# PRCM register map
Vendor: Texas Instruments
Peripheral module from a debugger description file (folder CC26x4).
Registers are 32-bit, access per field, reset 0x0 unless marked. A register's access mark holds for its fields unless they carry their own. Offsets are as the file gives them; lines under a group give offsets from that group; [hi:lo] are bit positions; {n}, {i} and the like mark numbered series; 'fields as' and 'values as' point back to an identical list; <NAME> marks a mode.

## PRCM — Power, Reset and Clock Management
0x00 INFRCLKDIVR — Infrastructure Clock Division Factor For Run Mode
  [1:0] RATIO rw — Division rate for clocks driving modules in the MCU_AON domain when system CPU is in run mode. Division ratio affects both infrastructure clock and perbusull clock.
    3=DIV32 (Divide by 32); 2=DIV8 (Divide by 8); 1=DIV2 (Divide by 2); 0=DIV1 (Divide by 1)
0x04 INFRCLKDIVS — Infrastructure Clock Division Factor For Sleep Mode
  [1:0] RATIO rw — Division rate for clocks driving modules in the MCU_AON domain when system CPU is in sleep mode. Division ratio affects both infrastructure clock and perbusull clock.
    values as INFRCLKDIVR.RATIO
0x08 INFRCLKDIVDS — Infrastructure Clock Division Factor For DeepSleep Mode
  [1:0] RATIO rw — Division rate for clocks driving modules in the MCU_AON domain when system CPU is in deepsleep mode. Division ratio affects both infrastructure clock and perbusull clock.
    values as INFRCLKDIVR.RATIO
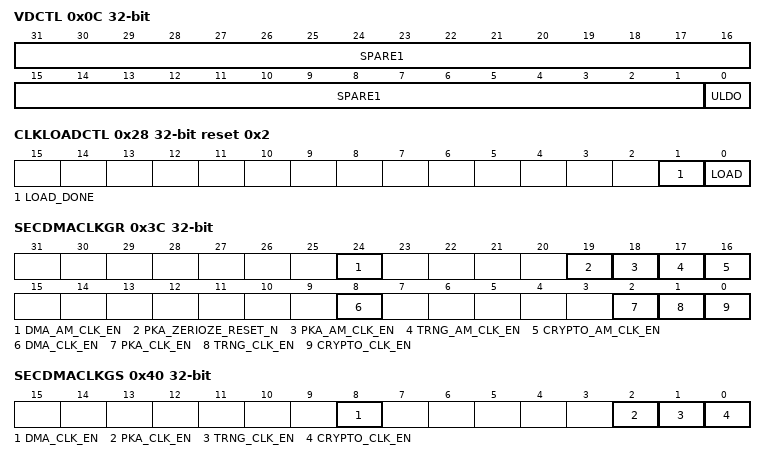
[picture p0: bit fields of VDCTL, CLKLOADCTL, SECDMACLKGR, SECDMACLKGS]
0x0C VDCTL rw — MCU Voltage Domain Control
  [31:1] SPARE1 — Software should not rely on the value of a reserved. Writing any other value than the reset value may result in undefined behavior.
  [0] ULDO — Request PMCTL to switch to uLDO. 0: No request 1: Assert request when possible The bit will have no effect before the following requirements are met: 1. PDCTL1.CPU_ON = 0 2. PDCTL1.VIMS_MODE = x0 3. SECDMACLKGDS.DMA_CLK_EN = 0 and S.CRYPTO_CLK_EN] = 0 and SECDMACLKGR.DMA_AM_CLK_EN = 0 (Note: Settings must be loaded with CLKLOADCTL.LOAD) 4. SECDMACLKGDS.CRYPTO_CLK_EN = 0 and SECDMACLKGR.CRYPTO_AM_CLK_EN = 0 (Note: Settings must be loaded with CLKLOADCTL.LOAD) 5. I2SCLKGDS.CLK_EN = 0 and I2SCLKGR.AM_CLK_EN = 0 (Note: Settings must be loaded with CLKLOADCTL.LOAD) 6. RFC do no request access to BUS 7. System CPU in deepsleep
0x28 CLKLOADCTL reset 0x2 — Load PRCM Settings To CLKCTRL Power Domain
  [1] LOAD_DONE ro — Status of LOAD. Will be cleared to 0 when any of the registers requiring a LOAD is written to, and be set to 1 when a LOAD is done. Note that writing no change to a register will result in the LOAD_DONE being cleared. 0 : One or more registers have been write accessed after last LOAD 1 : No registers are write accessed after last LOAD
  [0] LOAD wo — 0: No action 1: Load settings to CLKCTRL. Bit is HW cleared. Multiple changes to settings may be done before LOAD is written once so all changes takes place at the same time. LOAD can also be done after single setting updates. Registers that needs to be followed by LOAD before settings being applied are: - SYSBUSCLKDIV - CPUCLKDIV - PERBUSCPUCLKDIV - PERDMACLKDIV - PERBUSCPUCLKG - RFCCLKG - VIMSCLKG - SECDMACLKGR - SECDMACLKGS - SECDMACLKGDS - GPIOCLKGR - GPIOCLKGS - GPIOCLKGDS - GPTCLKGR - GPTCLKGS - GPTCLKGDS - GPTCLKDIV - I2CCLKGR - I2CCLKGS - I2CCLKGDS - SPICLKGR - SPICLKGS - SPICLKGDS - UARTCLKGR - UARTCLKGS - UARTCLKGDS - I2SCLKGR - I2SCLKGS - I2SCLKGDS - I2SBCLKSEL - I2SCLKCTL - I2SMCLKDIV - I2SBCLKDIV - I2SWCLKDIV - MCUSRAMCFG
0x2C RFCCLKG reset 0x1 — RFC Clock Gate
  [0] CLK_EN rw — 0: Disable Clock 1: Enable clock if RFC power domain is on For changes to take effect, CLKLOADCTL.LOAD needs to be written
0x30 VIMSCLKG reset 0x3 — VIMS Clock Gate
  [1:0] CLK_EN rw — 00: Disable clock 01: Disable clock when SYSBUS clock is disabled 11: Enable clock For changes to take effect, CLKLOADCTL.LOAD needs to be written
0x3C SECDMACLKGR — SEC (PKA And TRNG And CRYPTO) And UDMA Clock Gate For Run And All Modes
  [24] DMA_AM_CLK_EN rw — 0: No force 1: Force clock on for all modes (Run, Sleep and Deep Sleep) Overrides DMA_CLK_EN, SECDMACLKGS.DMA_CLK_EN and SECDMACLKGDS.DMA_CLK_EN when enabled. SYSBUS clock will always run when enabled For changes to take effect, CLKLOADCTL.LOAD needs to be written
  [19] PKA_ZERIOZE_RESET_N rw — Zeroization logic hardware reset. 0: pka_zeroize logic inactive. 1: pka_zeroize of memory is enabled. This register must remain active until the memory are completely zeroized which requires 256 periods on systembus clock.
  [18] PKA_AM_CLK_EN rw — 0: No force 1: Force clock on for all modes (Run, Sleep and Deep Sleep) Overrides PKA_CLK_EN, SECDMACLKGS.PKA_CLK_EN and SECDMACLKGDS.PKA_CLK_EN when enabled. For changes to take effect, CLKLOADCTL.LOAD needs to be written
  [17] TRNG_AM_CLK_EN rw — 0: No force 1: Force clock on for all modes (Run, Sleep and Deep Sleep) Overrides TRNG_CLK_EN, SECDMACLKGS.TRNG_CLK_EN and SECDMACLKGDS.TRNG_CLK_EN when enabled. For changes to take effect, CLKLOADCTL.LOAD needs to be written
  [16] CRYPTO_AM_CLK_EN rw — 0: No force 1: Force clock on for all modes (Run, Sleep and Deep Sleep) Overrides CRYPTO_CLK_EN, SECDMACLKGS.CRYPTO_CLK_EN and SECDMACLKGDS.CRYPTO_CLK_EN when enabled. SYSBUS clock will always run when enabled For changes to take effect, CLKLOADCTL.LOAD needs to be written
  [8] DMA_CLK_EN rw — 0: Disable clock 1: Enable clock Can be forced on by DMA_AM_CLK_EN For changes to take effect, CLKLOADCTL.LOAD needs to be written
  [2] PKA_CLK_EN rw — 0: Disable clock 1: Enable clock Can be forced on by PKA_AM_CLK_EN For changes to take effect, CLKLOADCTL.LOAD needs to be written
  [1] TRNG_CLK_EN rw — 0: Disable clock 1: Enable clock Can be forced on by TRNG_AM_CLK_EN For changes to take effect, CLKLOADCTL.LOAD needs to be written
  [0] CRYPTO_CLK_EN rw — 0: Disable clock 1: Enable clock Can be forced on by CRYPTO_AM_CLK_EN For changes to take effect, CLKLOADCTL.LOAD needs to be written
0x40 SECDMACLKGS — SEC (PKA And TRNG And CRYPTO) And UDMA Clock Gate For Sleep Mode
  [8] DMA_CLK_EN rw — 0: Disable clock 1: Enable clock Can be forced on by SECDMACLKGR.DMA_AM_CLK_EN For changes to take effect, CLKLOADCTL.LOAD needs to be written
  [2] PKA_CLK_EN rw — 0: Disable clock 1: Enable clock Can be forced on by SECDMACLKGR.PKA_AM_CLK_EN For changes to take effect, CLKLOADCTL.LOAD needs to be written
  [1] TRNG_CLK_EN rw — 0: Disable clock 1: Enable clock Can be forced on by SECDMACLKGR.TRNG_AM_CLK_EN For changes to take effect, CLKLOADCTL.LOAD needs to be written
  [0] CRYPTO_CLK_EN rw — 0: Disable clock 1: Enable clock Can be forced on by SECDMACLKGR.CRYPTO_AM_CLK_EN For changes to take effect, CLKLOADCTL.LOAD needs to be written
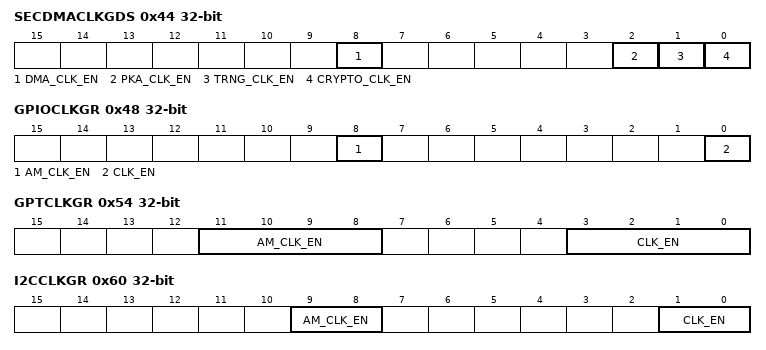
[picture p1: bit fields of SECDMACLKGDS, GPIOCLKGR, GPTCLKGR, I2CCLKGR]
0x44 SECDMACLKGDS — SEC (PKA And TRNG and CRYPTO) And UDMA Clock Gate For Deep Sleep Mode
  [8] DMA_CLK_EN rw — 0: Disable clock 1: Enable clock Can be forced on by SECDMACLKGR.DMA_AM_CLK_EN For changes to take effect, CLKLOADCTL.LOAD needs to be written
  [2] PKA_CLK_EN rw — 0: Disable clock 1: Enable clock Can be forced on by SECDMACLKGR.PKA_AM_CLK_EN For changes to take effect, CLKLOADCTL.LOAD needs to be written
  [1] TRNG_CLK_EN rw — 0: Disable clock 1: Enable clock SYSBUS clock will always run when enabled Can be forced on by SECDMACLKGR.TRNG_AM_CLK_EN For changes to take effect, CLKLOADCTL.LOAD needs to be written
  [0] CRYPTO_CLK_EN rw — 0: Disable clock 1: Enable clock SYSBUS clock will always run when enabled Can be forced on by SECDMACLKGR.CRYPTO_AM_CLK_EN For changes to take effect, CLKLOADCTL.LOAD needs to be written
0x48 GPIOCLKGR — GPIO Clock Gate For Run And All Modes
  [8] AM_CLK_EN rw — 0: No force 1: Force clock on for all modes (Run, Sleep and Deep Sleep) Overrides CLK_EN, GPIOCLKGS.CLK_EN and GPIOCLKGDS.CLK_EN when enabled. For changes to take effect, CLKLOADCTL.LOAD needs to be written
  [0] CLK_EN rw — 0: Disable clock 1: Enable clock Can be forced on by AM_CLK_EN For changes to take effect, CLKLOADCTL.LOAD needs to be written
0x4C GPIOCLKGS — GPIO Clock Gate For Sleep Mode
  [0] CLK_EN rw — 0: Disable clock 1: Enable clock Can be forced on by GPIOCLKGR.AM_CLK_EN For changes to take effect, CLKLOADCTL.LOAD needs to be written
0x50 GPIOCLKGDS — GPIO Clock Gate For Deep Sleep Mode
  fields as GPIOCLKGS
0x54 GPTCLKGR — GPT Clock Gate For Run And All Modes
  [11:8] AM_CLK_EN rw — Each bit below has the following meaning: 0: No force 1: Force clock on for all modes (Run, Sleep and Deep Sleep) Overrides CLK_EN, GPTCLKGS.CLK_EN and GPTCLKGDS.CLK_EN when enabled. ENUMs can be combined For changes to take effect, CLKLOADCTL.LOAD needs to be written
    8=AM_GPT3 (Enable clock for GPT3 in all modes); 4=AM_GPT2 (Enable clock for GPT2 in all modes); 2=AM_GPT1 (Enable clock for GPT1 in all modes); 1=AM_GPT0 (Enable clock for GPT0 in all modes)
  [3:0] CLK_EN rw — Each bit below has the following meaning: 0: Disable clock 1: Enable clock Can be forced on by AM_CLK_EN ENUMs can be combined For changes to take effect, CLKLOADCTL.LOAD needs to be written
    8=GPT3 (Enable clock for GPT3); 4=GPT2 (Enable clock for GPT2); 2=GPT1 (Enable clock for GPT1); 1=GPT0 (Enable clock for GPT0)
0x58 GPTCLKGS — GPT Clock Gate For Sleep Mode
  [3:0] CLK_EN rw — Each bit below has the following meaning: 0: Disable clock 1: Enable clock Can be forced on by GPTCLKGR.AM_CLK_EN ENUMs can be combined For changes to take effect, CLKLOADCTL.LOAD needs to be written
    values as GPTCLKGR.CLK_EN
0x5C GPTCLKGDS — GPT Clock Gate For Deep Sleep Mode
  fields as GPTCLKGS
0x60 I2CCLKGR — I2C Clock Gate For Run And All Modes
  [9:8] AM_CLK_EN rw — 0: No force 1: Force clock on for all modes (Run, Sleep and Deep Sleep) Overrides CLK_EN, I2CCLKGS.CLK_EN and I2CCLKGDS.CLK_EN when enabled. For changes to take effect, CLKLOADCTL.LOAD needs to be written
    2=I2C1 (Enable clock for I2C1); 1=I2C0 (Enable clock for I2C0)
  [1:0] CLK_EN rw — 0: Disable clock 1: Enable clock Can be forced on by AM_CLK_EN For changes to take effect, CLKLOADCTL.LOAD needs to be written
    values as AM_CLK_EN
0x64 I2CCLKGS — I2C Clock Gate For Sleep Mode
  [1:0] CLK_EN rw — 0: Disable clock 1: Enable clock Can be forced on by I2CCLKGR.AM_CLK_EN For changes to take effect, CLKLOADCTL.LOAD needs to be written
    values as I2CCLKGR.AM_CLK_EN
0x68 I2CCLKGDS — I2C Clock Gate For Deep Sleep Mode
  [0] CLK_EN rw — 0: Disable clock 1: Enable clock Can be forced on by I2CCLKGR.AM_CLK_EN For changes to take effect, CLKLOADCTL.LOAD needs to be written
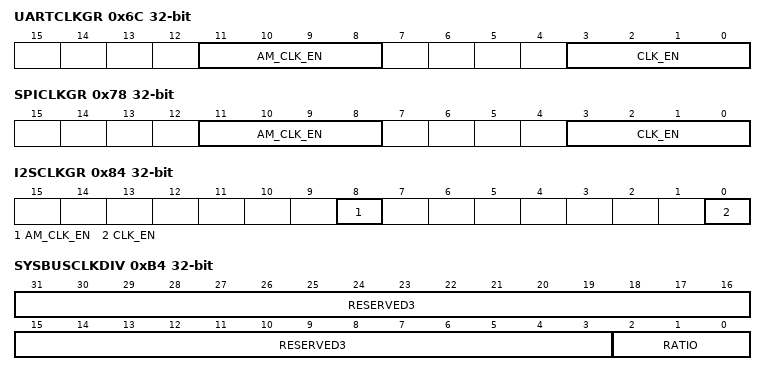
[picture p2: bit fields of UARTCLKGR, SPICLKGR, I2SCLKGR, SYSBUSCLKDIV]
0x6C UARTCLKGR — UART Clock Gate For Run And All Modes
  [11:8] AM_CLK_EN rw — 0: No force 1: Force clock on for all modes (Run, Sleep and Deep Sleep) Overrides CLK_EN, UARTCLKGS.CLK_EN and UARTCLKGDS.CLK_EN when enabled. For changes to take effect, CLKLOADCTL.LOAD needs to be written
    8=UART3 (Enable clock for UART3); 4=UART2 (Enable clock for UART2); 2=UART1 (Enable clock for UART1); 1=UART0 (Enable clock for UART0)
  [3:0] CLK_EN rw — 0: Disable clock 1: Enable clock Can be forced on by AM_CLK_EN For changes to take effect, CLKLOADCTL.LOAD needs to be written
    values as AM_CLK_EN
0x70 UARTCLKGS — UART Clock Gate For Sleep Mode
  [3:0] CLK_EN rw — 0: Disable clock 1: Enable clock Can be forced on by UARTCLKGR.AM_CLK_EN For changes to take effect, CLKLOADCTL.LOAD needs to be written
    values as UARTCLKGR.AM_CLK_EN
0x74 UARTCLKGDS — UART Clock Gate For Deep Sleep Mode
  fields as UARTCLKGS
0x78 SPICLKGR — SPI Clock Gate For Run And All Modes
  [11:8] AM_CLK_EN rw — 0: No force 1: Force clock on for all modes (Run, Sleep and Deep Sleep) Overrides CLK_EN, SPICLKGS.CLK_EN and SPICLKGDS.CLK_EN when enabled. For changes to take effect, CLKLOADCTL.LOAD needs to be written
    8=SPI3 (Enable clock for SPI3); 4=SPI2 (Enable clock for SPI2); 2=SPI1 (Enable clock for SPI1); 1=SPI0 (Enable clock for SPI0)
  [3:0] CLK_EN rw — 0: Disable clock 1: Enable clock Can be forced on by AM_CLK_EN For changes to take effect, CLKLOADCTL.LOAD needs to be written
    values as AM_CLK_EN
0x7C SPICLKGS — SPI Clock Gate For Sleep Mode
  [3:0] CLK_EN rw — 0: Disable clock 1: Enable clock Can be forced on by SPICLKGR.AM_CLK_EN For changes to take effect, CLKLOADCTL.LOAD needs to be written
    values as SPICLKGR.AM_CLK_EN
0x80 SPICLKGDS — SPI Clock Gate For Deep Sleep Mode
  fields as SPICLKGS
0x84 I2SCLKGR — I2S Clock Gate For Run And All Modes
  [8] AM_CLK_EN rw — 0: No force 1: Force clock on for all modes (Run, Sleep and Deep Sleep) Overrides CLK_EN, I2SCLKGS.CLK_EN and I2SCLKGDS.CLK_EN when enabled. SYSBUS clock will always run when enabled For changes to take effect, CLKLOADCTL.LOAD needs to be written
  [0] CLK_EN rw — 0: Disable clock 1: Enable clock Can be forced on by AM_CLK_EN For changes to take effect, CLKLOADCTL.LOAD needs to be written
0x88 I2SCLKGS — I2S Clock Gate For Sleep Mode
  [0] CLK_EN rw — 0: Disable clock 1: Enable clock Can be forced on by I2SCLKGR.AM_CLK_EN For changes to take effect, CLKLOADCTL.LOAD needs to be written
0x8C I2SCLKGDS — I2S Clock Gate For Deep Sleep Mode
  [0] CLK_EN rw — 0: Disable clock 1: Enable clock SYSBUS clock will always run when enabled Can be forced on by I2SCLKGR.AM_CLK_EN For changes to take effect, CLKLOADCTL.LOAD needs to be written
0xB4 SYSBUSCLKDIV — Internal. Only to be used through TI provided API.
  [31:3] RESERVED3 ro — Internal. Only to be used through TI provided API.
  [2:0] RATIO rw — Internal. Only to be used through TI provided API.
    1=DIV2 (Internal. Only to be used through TI provided API.); 0=DIV1 (Internal. Only to be used through TI provided API.)
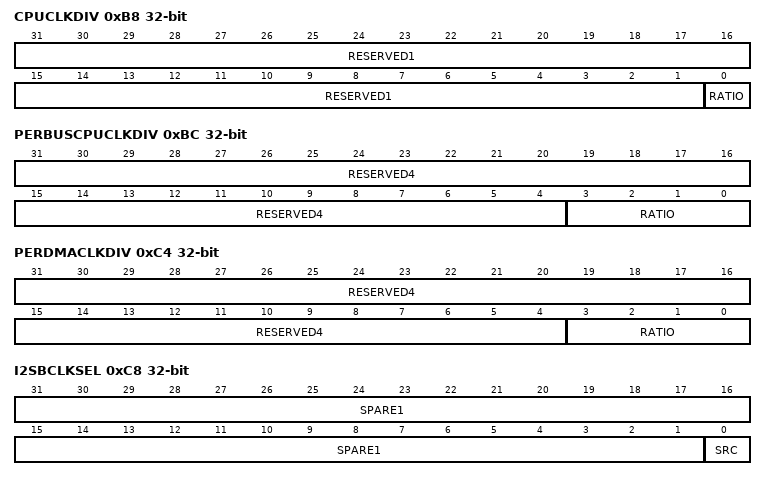
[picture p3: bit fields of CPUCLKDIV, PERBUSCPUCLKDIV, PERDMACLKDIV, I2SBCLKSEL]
0xB8 CPUCLKDIV — Internal. Only to be used through TI provided API.
  [31:1] RESERVED1 ro — Internal. Only to be used through TI provided API.
  [0] RATIO rw — Internal. Only to be used through TI provided API.
    0=DIV1 (Internal. Only to be used through TI provided API.)
0xBC PERBUSCPUCLKDIV — Internal. Only to be used through TI provided API.
  [31:4] RESERVED4 ro — Internal. Only to be used through TI provided API.
  [3:0] RATIO rw — Internal. Only to be used through TI provided API.
    8=DIV256 (Internal. Only to be used through TI provided API.); 7=DIV128 (Internal. Only to be used through TI provided API.); 6=DIV64 (Internal. Only to be used through TI provided API.); 5=DIV32 (Internal. Only to be used through TI provided API.); 4=DIV16 (Internal. Only to be used through TI provided API.); 3=DIV8 (Internal. Only to be used through TI provided API.); 2=DIV4 (Internal. Only to be used through TI provided API.); 1=DIV2 (Internal. Only to be used through TI provided API.); 0=DIV1 (Internal. Only to be used through TI provided API.)
0xC0 PERBUSDMACLKDIV rw — Internal. Only to be used through TI provided API.
  [31:0] SPARE0
0xC4 PERDMACLKDIV — Internal. Only to be used through TI provided API.
  fields as PERBUSCPUCLKDIV
0xC8 I2SBCLKSEL rw — I2S Clock Control
  [31:1] SPARE1 — Software should not rely on the value of a reserved. Writing any other value than the reset value may result in undefined behavior.
  [0] SRC — BCLK source selector 0: Use external BCLK 1: Use internally generated clock For changes to take effect, CLKLOADCTL.LOAD needs to be written
0xCC GPTCLKDIV — GPT Scalar
  [3:0] RATIO rw — Scalar used for GPTs. The division rate will be constant and ungated for Run / Sleep / DeepSleep mode. For changes to take effect, CLKLOADCTL.LOAD needs to be written Other values are not supported.
    8=DIV256 (Divide by 256); 7=DIV128 (Divide by 128); 6=DIV64 (Divide by 64); 5=DIV32 (Divide by 32); 4=DIV16 (Divide by 16); 3=DIV8 (Divide by 8); 2=DIV4 (Divide by 4); 1=DIV2 (Divide by 2); 0=DIV1 (Divide by 1)
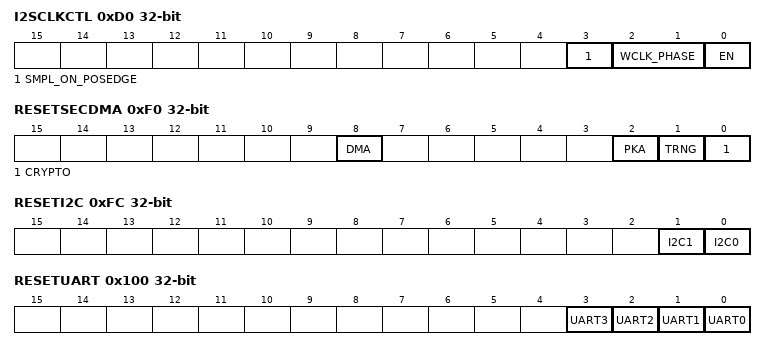
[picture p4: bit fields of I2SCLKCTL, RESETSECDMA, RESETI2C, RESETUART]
0xD0 I2SCLKCTL — I2S Clock Control
  [3] SMPL_ON_POSEDGE rw — On the I2S serial interface, data and WCLK is sampled and clocked out on opposite edges of BCLK. 0 - data and WCLK are sampled on the negative edge and clocked out on the positive edge. 1 - data and WCLK are sampled on the positive edge and clocked out on the negative edge. For changes to take effect, CLKLOADCTL.LOAD needs to be written
  [2:1] WCLK_PHASE rw — Decides how the WCLK division ratio is calculated and used to generate different duty cycles (See I2SWCLKDIV.WDIV). 0: Single phase 1: Dual phase 2: User Defined 3: Reserved/Undefined For changes to take effect, CLKLOADCTL.LOAD needs to be written
  [0] EN rw — 0: MCLK, BCLK and WCLK will be static low 1: Enables the generation of MCLK, BCLK and WCLK For changes to take effect, CLKLOADCTL.LOAD needs to be written
0xD4 I2SMCLKDIV — MCLK Division Ratio
  [9:0] MDIV rw — An unsigned factor of the division ratio used to generate MCLK [2-1024]: MCLK = MCUCLK/MDIV[Hz] MCUCLK is 48MHz. A value of 0 is interpreted as 1024. A value of 1 is invalid. If MDIV is odd the low phase of the clock is one MCUCLK period longer than the high phase. For changes to take effect, CLKLOADCTL.LOAD needs to be written
0xD8 I2SBCLKDIV — BCLK Division Ratio
  [9:0] BDIV rw — An unsigned factor of the division ratio used to generate I2S BCLK [2-1024]: BCLK = MCUCLK/BDIV[Hz] MCUCLK is 48MHz. A value of 0 is interpreted as 1024. A value of 1 is invalid. If BDIV is odd and I2SCLKCTL.SMPL_ON_POSEDGE = 0, the low phase of the clock is one MCUCLK period longer than the high phase. If BDIV is odd and I2SCLKCTL.SMPL_ON_POSEDGE = 1 , the high phase of the clock is one MCUCLK period longer than the low phase. For changes to take effect, CLKLOADCTL.LOAD needs to be written
0xDC I2SWCLKDIV — WCLK Division Ratio
  [15:0] WDIV rw — If I2SCLKCTL.WCLK_PHASE = 0, Single phase. WCLK is high one BCLK period and low WDIV[9:0] (unsigned, [1-1023]) BCLK periods. WCLK = MCUCLK / BDIV*(WDIV[9:0] + 1) [Hz] MCUCLK is 48MHz. If I2SCLKCTL.WCLK_PHASE = 1, Dual phase. Each phase on WCLK (50% duty cycle) is WDIV[9:0] (unsigned, [1-1023]) BCLK periods. WCLK = MCUCLK / BDIV*(2*WDIV[9:0]) [Hz] If I2SCLKCTL.WCLK_PHASE = 2, User defined. WCLK is high WDIV[7:0] (unsigned, [1-255]) BCLK periods and low WDIV[15:8] (unsigned, [1-255]) BCLK periods. WCLK = MCUCLK / (BDIV*(WDIV[7:0] + WDIV[15:8]) [Hz] For changes to take effect, CLKLOADCTL.LOAD needs to be written
0xF0 RESETSECDMA — RESET For SEC (PKA And TRNG And CRYPTO) And UDMA
  [8] DMA wo — Write 1 to reset. HW cleared. Access will only have effect when PERIPH power domain is on, PDSTAT0.PERIPH_ON = 1 Before writing set FLASH:CFG.DIS_READACCESS = 1 to ensure the reset is not activated while executing from flash. This means one cannot execute from flash when using the SW reset.
  [2] PKA wo — Write 1 to reset. HW cleared. Access will only have effect when PERIPH power domain is on, PDSTAT0.PERIPH_ON = 1 Before writing set FLASH:CFG.DIS_READACCESS = 1 to ensure the reset is not activated while executing from flash. This means one cannot execute from flash when using the SW reset.
  [1] TRNG wo — Write 1 to reset. HW cleared. Access will only have effect when PERIPH power domain is on, PDSTAT0.PERIPH_ON = 1 Before writing set FLASH:CFG.DIS_READACCESS = 1 to ensure the reset is not activated while executing from flash. This means one cannot execute from flash when using the SW reset.
  [0] CRYPTO wo — Write 1 to reset. HW cleared. Access will only have effect when PERIPH power domain is on, PDSTAT0.PERIPH_ON = 1 Before writing set FLASH:CFG.DIS_READACCESS = 1 to ensure the reset is not activated while executing from flash. This means one cannot execute from flash when using the SW reset.
0xF4 RESETGPIO — RESET For GPIO IPs
  [0] GPIO wo — 0: No action 1: Reset GPIO. HW cleared. Access will only have effect when PERIPH power domain is on, PDSTAT0.PERIPH_ON = 1 Before writing set FLASH:CFG.DIS_READACCESS = 1 to ensure the reset is not activated while executing from flash. This means one cannot execute from flash when using the SW reset.
0xF8 RESETGPT — RESET For GPT Ips
  [0] GPT wo — 0: No action 1: Reset all GPTs. HW cleared. Access will only have effect when PERIPH power domain is on, PDSTAT0.PERIPH_ON = 1 Before writing set FLASH:CFG.DIS_READACCESS = 1 to ensure the reset is not activated while executing from flash. This means one cannot execute from flash when using the SW reset.
0xFC RESETI2C — RESET For I2C IPs
  [1] I2C1 wo — 0: No action 1: Reset I2C1. HW cleared. Access will only have effect when PERIPH power domain is on, PDSTAT0.PERIPH_ON = 1 Before writing set FLASH:CFG.DIS_READACCESS = 1 to ensure the reset is not activated while executing from flash. This means one cannot execute from flash when using the SW reset.
  [0] I2C0 wo — 0: No action 1: Reset I2C0. HW cleared. Access will only have effect when SERIAL power domain is on, PDSTAT0.SERIAL_ON = 1 Before writing set FLASH:CFG.DIS_READACCESS = 1 to ensure the reset is not activated while executing from flash. This means one cannot execute from flash when using the SW reset.
0x100 RESETUART — RESET For UART IPs
  [3] UART3 wo — 0: No action 1: Reset UART3. HW cleared. Access will only have effect when PERIPH power domain is on, PDSTAT0.PERIPH_ON = 1 Before writing set FLASH:CFG.DIS_READACCESS = 1 to ensure the reset is not activated while executing from flash. This means one cannot execute from flash when using the SW reset.
  [2] UART2 wo — 0: No action 1: Reset UART2. HW cleared. Access will only have effect when PERIPH power domain is on, PDSTAT0.PERIPH_ON = 1 Before writing set FLASH:CFG.DIS_READACCESS = 1 to ensure the reset is not activated while executing from flash. This means one cannot execute from flash when using the SW reset.
  [1] UART1 wo — 0: No action 1: Reset UART1. HW cleared. Access will only have effect when PERIPH power domain is on, PDSTAT0.PERIPH_ON = 1 Before writing set FLASH:CFG.DIS_READACCESS = 1 to ensure the reset is not activated while executing from flash. This means one cannot execute from flash when using the SW reset.
  [0] UART0 wo — 0: No action 1: Reset UART0. HW cleared. Access will only have effect when SERIAL power domain is on, PDSTAT0.SERIAL_ON = 1 Before writing set FLASH:CFG.DIS_READACCESS = 1 to ensure the reset is not activated while executing from flash. This means one cannot execute from flash when using the SW reset.
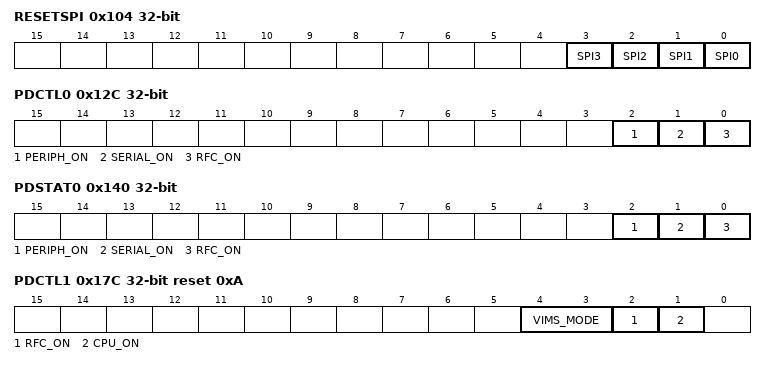
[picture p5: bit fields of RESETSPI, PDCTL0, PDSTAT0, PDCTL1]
0x104 RESETSPI — RESET For SPI IPs
  [3] SPI3 wo — 0: No action 1: Reset SPI3. HW cleared. Access will only have effect when PERIPH power domain is on, PDSTAT0.PERIPH_ON = 1 Before writing set FLASH:CFG.DIS_READACCESS = 1 to ensure the reset is not activated while executing from flash. This means one cannot execute from flash when using the SW reset.
  [2] SPI2 wo — 0: No action 1: Reset SPI2. HW cleared. Access will only have effect when PERIPH power domain is on, PDSTAT0.PERIPH_ON = 1 Before writing set FLASH:CFG.DIS_READACCESS = 1 to ensure the reset is not activated while executing from flash. This means one cannot execute from flash when using the SW reset.
  [1] SPI1 wo — 0: No action 1: Reset SPI1. HW cleared. Access will only have effect when PERIPH power domain is on, PDSTAT0.PERIPH_ON = 1 Before writing set FLASH:CFG.DIS_READACCESS = 1 to ensure the reset is not activated while executing from flash. This means one cannot execute from flash when using the SW reset.
  [0] SPI0 wo — 0: No action 1: Reset SPI0. HW cleared. Access will only have effect when SERIAL power domain is on, PDSTAT0.SERIAL_ON = 1 Before writing set FLASH:CFG.DIS_READACCESS = 1 to ensure the reset is not activated while executing from flash. This means one cannot execute from flash when using the SW reset.
0x108 RESETI2S — RESET For I2S IP
  [0] I2S wo — 0: No action 1: Reset module. HW cleared. Access will only have effect when PERIPH power domain is on, PDSTAT0.PERIPH_ON = 1 Before writing set FLASH:CFG.DIS_READACCESS = 1 to ensure the reset is not activated while executing from flash. This means one cannot execute from flash when using the SW reset.
0x12C PDCTL0 — Power Domain Control
  [2] PERIPH_ON rw — PERIPH Power domain. 0: PERIPH power domain is powered down 1: PERIPH power domain is powered up
  [1] SERIAL_ON rw — SERIAL Power domain. 0: SERIAL power domain is powered down 1: SERIAL power domain is powered up
  [0] RFC_ON rw — 0: RFC power domain powered off if also PDCTL1.RFC_ON = 0 1: RFC power domain powered on
0x130 PDCTL0RFC — RFC Power Domain Control
  [0] ON rw — Alias for PDCTL0.RFC_ON
0x134 PDCTL0SERIAL — SERIAL Power Domain Control
  [0] ON rw — Alias for PDCTL0.SERIAL_ON
0x138 PDCTL0PERIPH — PERIPH Power Domain Control
  [0] ON rw — Alias for PDCTL0.PERIPH_ON
0x140 PDSTAT0 ro — Power Domain Status
  [2] PERIPH_ON — PERIPH Power domain. 0: Domain may be powered down 1: Domain powered up (guaranteed)
  [1] SERIAL_ON — SERIAL Power domain. 0: Domain may be powered down 1: Domain powered up (guaranteed)
  [0] RFC_ON — RFC Power domain 0: Domain may be powered down 1: Domain powered up (guaranteed)
0x144 PDSTAT0RFC ro — RFC Power Domain Status
  [0] ON — Alias for PDSTAT0.RFC_ON
0x148 PDSTAT0SERIAL ro — SERIAL Power Domain Status
  [0] ON — Alias for PDSTAT0.SERIAL_ON
0x14C PDSTAT0PERIPH ro — PERIPH Power Domain Status
  [0] ON — Alias for PDSTAT0.PERIPH_ON
0x17C PDCTL1 reset 0xA — Power Domain Control
  [4:3] VIMS_MODE rw — 00: VIMS power domain is only powered when CPU power domain is powered. 01: VIMS power domain is powered whenever the BUS power domain is powered. 1X: Block power up of VIMS power domain at next wake up. This mode only has effect when VIMS power domain is not powered. Used for Autonomous RF Core.
  [2] RFC_ON rw — 0: RFC power domain powered off if also PDCTL0.RFC_ON = 0 1: RFC power domain powered on Bit shall be used by RFC in autonomous mode but there is no HW restrictions from system CPU to access the bit.
  [1] CPU_ON rw — 0: Causes a power down of the CPU power domain when system CPU indicates it is idle. 1: Initiates power-on of the CPU power domain. This bit is automatically set by a WIC power-on event.
0x184 PDCTL1CPU reset 0x1 — CPU Power Domain Direct Control
  [0] ON rw — This is an alias for PDCTL1.CPU_ON
0x188 PDCTL1RFC — RFC Power Domain Direct Control
  [0] ON rw — This is an alias for PDCTL1.RFC_ON
0x18C PDCTL1VIMS reset 0x1 — VIMS Mode Direct Control
  [1:0] MODE rw — This is an alias for PDCTL1.VIMS_MODE
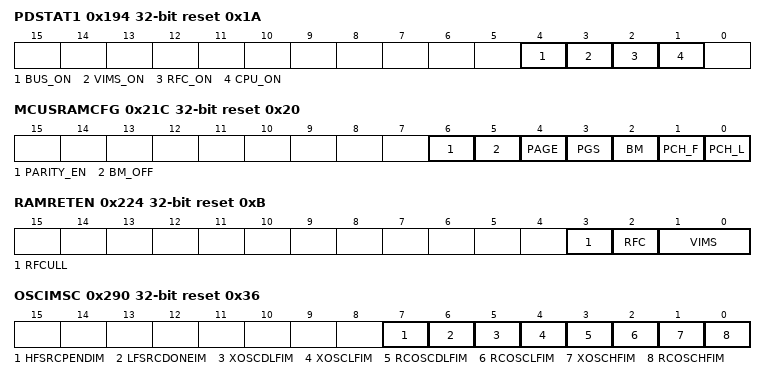
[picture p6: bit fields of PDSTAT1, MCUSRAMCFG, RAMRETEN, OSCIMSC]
0x194 PDSTAT1 ro reset 0x1A — Power Manager Status
  [4] BUS_ON — 0: BUS domain not accessible 1: BUS domain is currently accessible
  [3] VIMS_ON — 0: VIMS domain not accessible 1: VIMS domain is currently accessible
  [2] RFC_ON — 0: RFC domain not accessible 1: RFC domain is currently accessible
  [1] CPU_ON — 0: CPU and BUS domain not accessible 1: CPU and BUS domains are both currently accessible
0x198 PDSTAT1BUS ro reset 0x1 — BUS Power Domain Direct Read Status
  [0] ON — This is an alias for PDSTAT1.BUS_ON
0x19C PDSTAT1RFC ro — RFC Power Domain Direct Read Status
  [0] ON — This is an alias for PDSTAT1.RFC_ON
0x1A0 PDSTAT1CPU ro reset 0x1 — CPU Power Domain Direct Read Status
  [0] ON — This is an alias for PDSTAT1.CPU_ON
0x1A4 PDSTAT1VIMS ro reset 0x1 — VIMS Mode Direct Read Status
  [0] ON — This is an alias for PDSTAT1.VIMS_ON
0x1CC RFCBITS rw — Control To RFC
  [31:0] READ — Control bits for RFC. The RF core CPE processor will automatically check this register when it boots, and it can be used to immediately instruct CPE to perform some tasks at its start-up. The supported functionality is ROM-defined and may vary. See the technical reference manual for more details.
0x1D0 RFCMODESEL — Selected RFC Mode
  [2:0] CURR rw — Selects the set of commands that the RFC will accept. Only modes permitted by RFCMODEHWOPT.AVAIL are writable. See the technical reference manual for details.
    {v}=MODE{v} (Select Mode {v}) (v=0..7)
0x1D4 RFCMODEHWOPT ro — Allowed RFC Modes
  [7:0] AVAIL — Permitted RFC modes. More than one mode can be permitted.
    128=MODE7 (Mode 7 permitted); 64=MODE6 (Mode 6 permitted); 32=MODE5 (Mode 5 permitted); 16=MODE4 (Mode 4 permitted); 8=MODE3 (Mode 3 permitted); 4=MODE2 (Mode 2 permitted); 2=MODE1 (Mode 1 permitted); 1=MODE0 (Mode 0 permitted)
0x1E0 PWRPROFSTAT reset 0x1 — Power Profiler Register
  [7:0] VALUE rw — SW can use these bits to timestamp the application. These bits are also available through the testtap and can thus be used by the emulator to profile in real time.
0x21C MCUSRAMCFG reset 0x20 — MCU SRAM configuration
  [6] PARITY_EN rw — Parity enable 0: Parity disabled Parity section available as GPRAM 1: Parity enabled
  [5] BM_OFF rw — NOT in use. Writing any other value than the reset value may result in undefined behavior.
  [4] PAGE rw — NOT in use. Writing any other value than the reset value may result in undefined behavior.
  [3] PGS rw — NOT in use. Writing any other value than the reset value may result in undefined behavior.
  [2] BM rw — NOT in use. Writing any other value than the reset value may result in undefined behavior.
  [1] PCH_F rw — NOT in use. Writing any other value than the reset value may result in undefined behavior.
  [0] PCH_L rw — NOT in use. Writing any other value than the reset value may result in undefined behavior.
0x224 RAMRETEN reset 0xB — Memory Retention Control
  [3] RFCULL rw — 0: Retention for RFC ULL SRAM disabled 1: Retention for RFC ULL SRAM enabled Memories controlled: CPEULLRAM
  [2] RFC rw — 0: Retention for RFC SRAM disabled 1: Retention for RFC SRAM enabled Memories controlled: CPERAM MCERAM RFERAM DSBRAM
  [1:0] VIMS rw — 0: Memory retention disabled 1: Memory retention enabled Bit 0: VIMS_TRAM Bit 1: VIMS_CRAM Legal modes depend on settings in VIMS:CTL.MODE 00: VIMS:CTL.MODE must be OFF before DEEPSLEEP is asserted - must be set to CACHE or SPLIT mode after waking up again 01: VIMS:CTL.MODE must be GPRAM before DEEPSLEEP is asserted. Must remain in GPRAM mode after wake up, alternatively select OFF mode first and then CACHE or SPLIT mode. 10: Illegal mode 11: No restrictions
0x290 OSCIMSC reset 0x36 — Oscillator Interrupt Mask Control
  [7] HFSRCPENDIM rw — 0: Disable interrupt generation when HFSRCPEND is qualified 1: Enable interrupt generation when HFSRCPEND is qualified
  [6] LFSRCDONEIM rw — 0: Disable interrupt generation when LFSRCDONE is qualified 1: Enable interrupt generation when LFSRCDONE is qualified
  [5] XOSCDLFIM rw — 0: Disable interrupt generation when XOSCDLF is qualified 1: Enable interrupt generation when XOSCDLF is qualified
  [4] XOSCLFIM rw — 0: Disable interrupt generation when XOSCLF is qualified 1: Enable interrupt generation when XOSCLF is qualified
  [3] RCOSCDLFIM rw — 0: Disable interrupt generation when RCOSCDLF is qualified 1: Enable interrupt generation when RCOSCDLF is qualified
  [2] RCOSCLFIM rw — 0: Disable interrupt generation when RCOSCLF is qualified 1: Enable interrupt generation when RCOSCLF is qualified
  [1] XOSCHFIM rw — 0: Disable interrupt generation when XOSCHF is qualified 1: Enable interrupt generation when XOSCHF is qualified
  [0] RCOSCHFIM rw — 0: Disable interrupt generation when RCOSCHF is qualified 1: Enable interrupt generation when RCOSCHF is qualified
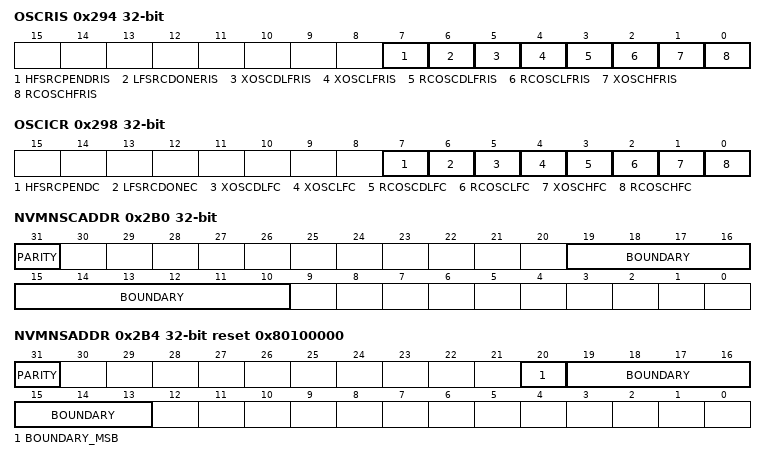
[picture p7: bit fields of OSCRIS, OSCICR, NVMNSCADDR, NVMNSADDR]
0x294 OSCRIS ro — Oscillator Raw Interrupt Status
  [7] HFSRCPENDRIS — SCLK_HF source switch pending interrupt. After a write to DDI_0_OSC:CTL0.SCLK_HF_SRC_SEL leads to a SCLK_HF source change request, then the requested SCLK_HF source will be enabled and qualified. When the new source is ready to be used as a clock source, then the interrupt HSSRCPENDRIS will go high. When the Flash allows SCLK_HF source switching to take place after flash memory read access is disabled. At this time the actual SCLK_HF clock source switch will be performed, and the interrupt status HSSRCPENDRIS will go low. 0: Indicates SCLK_HF source is not ready to be switched 1: Indicates SCLK_HF source is ready to be switched Interrupt is qualified regardless of OSCIMSC.HFSRCPENDIM setting. The order of qualifying raw interrupt and enable of interrupt mask is indifferent for generating an OSC Interrupt. Set by HW. Cleared by writing to OSCICR.HFSRCPENDC
  [6] LFSRCDONERIS — SCLK_LF source switch done. The DDI_0_OSC:CTL0.SCLK_LF_SRC_SEL register field is used to request that the SCLK_LF source shall be changed. After an SCLK_LF clock source change is requested, the new source may need to be enabled and qualified before switching of clock source can be done. The interrupt LFRSRCDONERIS goes high to indicate that the SCLK_LF clock source switching has been performed. LFRSRCDONERIS will go low again when the next clock source change is requested by writing to DDI_0_OSC:CTL0.SCLK_LF_SRC_SEL . 0: Indicates SCLK_LF source switch has not completed 1: Indicates SCLK_LF source switch has completed Interrupt is qualified regardless of OSCIMSC.LFSRCDONEIM setting. The order of qualifying raw interrupt and enable of interrupt mask is indifferent for generating an OSC Interrupt. Set by HW. Cleared by writing to OSCICR.LFSRCDONEC
  [5] XOSCDLFRIS — The XOSCDLFRIS interrupt indicates when the XOSC_HF oscillator is ready to be used as a derived low-frequency clock source for SCLK_LF or ACLK_REF. When XOSCDLFRIS is high, XOSC_HF will be used as source for SCLK_LF when selected. When none of the system clocks have XOSC_HF selected as clock source, the XOSC_HF source is automatically disabled and the XOSCDLFRIS interrupt status will go low. 0: XOSCDLF has not been qualified 1: XOSCDLF has been qualified Interrupt is qualified regardless of OSCIMSC.XOSCDLFIM setting. The order of qualifying raw interrupt and enable of interrupt mask is indifferent for generating an OSC Interrupt. Set by HW. Cleared by writing to OSCICR.XOSCDLFC
  [4] XOSCLFRIS — The XOSCLFRIS interrupt indicates when the output of the XOSC_LF oscillator has been qualified with respect to frequency. The XOSCLFRIS interrupt status goes high when the XOSC_LF oscillator is ready to be used as a clock source. After the clock qualification is successful, XOSCLFRIS interrupt status remains high, and further qualification is turned off until the XOSC_LF oscillator is disabled. XOSCLFRIS interrupt status will go low only at initial power-on, or after the XOSC_LF oscillator has been disabled when being deselected as a clock source. 0: XOSCLF has not been qualified 1: XOSCLF has been qualified Interrupt is qualified regardless of OSCIMSC.XOSCLFIM setting. The order of qualifying raw interrupt and enable of interrupt mask is indifferent for generating an OSC Interrupt. Set by HW. Cleared by writing to OSCICR.XOSCLFC
  [3] RCOSCDLFRIS — The RCOSCDLFRIS interrupt indicates when the RCOSC_HF oscillator is ready to be used as a derived low-frequency clock source for SCLK_LF or ACLK_REF. When RCOSCDLFRIS is high, RCOSC_HF will be used as source for SCLK_LF when selected. When none of the system clocks have RCOSC_HF selected as clock source, the RCOSC_HF source is automatically disabled and the RCOSCDLFRIS interrupt status will go low. If the SCLK_LF or ACLK_REF source is changed from RCOSC_HF derived to XOSC_HF derived low-frequency clock and the new source has not been qualified, then the clock will remain running on the original source. The RCOSCDLFRIS interrupt will then remain high. 0: RCOSCDLF has not been qualified 1: RCOSCDLF has been qualified Interrupt is qualified regardless of OSCIMSC.RCOSCDLFIM setting. The order of qualifying raw interrupt and enable of interrupt mask is indifferent for generating an OSC Interrupt. Set by HW. Cleared by writing to OSCICR.RCOSCDLFC
  [2] RCOSCLFRIS — The RCOSCLFRIS interrupt indicates when the output of the RCOSC_LF oscillator has been qualified with respect to frequency. The RCOSCLFRIS interrupt status goes high when the RCOSC_LF oscillator is ready to be used as a clock source. After the clock qualification is successful, RCOSCLFRIS interrupt status remains high, and further qualification is turned off until the RCOSC_LF oscillator is disabled. RCOSCLFRIS interrupt status will go low only at initial power-on, or after the RCOSC_LF oscillator has been disabled when being deselected as a clock source. 0: RCOSCLF has not been qualified 1: RCOSCLF has been qualified Interrupt is qualified regardless of OSCIMSC.RCOSCLFIM setting. The order of qualifying raw interrupt and enable of interrupt mask is indifferent for generating an OSC Interrupt. Set by HW. Cleared by writing to OSCICR.RCOSCLFC
  [1] XOSCHFRIS — The XOSCHFRIS interrupt indicates when the XOSC_HF oscillator has been qualified for use as a clock source. XOSCHFRIS is also used in TCXO mode (when DDI_0_OSC:XOSCHFCTL.TCXO_MODE is 1). When the XOSCHFRIS interrupt is high, the oscillator is qualified and will be used as a clock source when selected. The XOSCHFRIS interrupt goes low when the oscillator is disabled after being deselected as a clock source. 0: XOSC_HF has not been qualified 1: XOSC_HF has been qualified Interrupt is qualified regardless of OSCIMSC.XOSCHFIM setting. The order of qualifying raw interrupt and enable of interrupt mask is indifferent for generating an OSC Interrupt. Set by HW. Cleared by writing to OSCICR.XOSCHFC
  [0] RCOSCHFRIS — The RCOSCHFRIS interrupt indicates when the RCOSC_HF oscillator has been qualified for use as a clock source When the RCOSCHFRIS interrupt is high, the oscillator is qualified and will be used as a clock source when selected. The RCOSCHFRIS interrupt goes low when the oscillator is disabled after being deselected as a clock source. 0: RCOSC_HF has not been qualified 1: RCOSC_HF has been qualified Interrupt is qualified regardless of OSCIMSC.RCOSCHFIM setting. The order of qualifying raw interrupt and enable of interrupt mask is indifferent for generating an OSC Interrupt. Set by HW. Cleared by writing to OSCICR.RCOSCHFC
0x298 OSCICR wo — Oscillator Raw Interrupt Clear
  [7] HFSRCPENDC — Writing 1 to this field clears the HFSRCPEND raw interrupt status. Writing 0 has no effect.
  [6] LFSRCDONEC — Writing 1 to this field clears the LFSRCDONE raw interrupt status. Writing 0 has no effect.
  [5] XOSCDLFC — Writing 1 to this field clears the XOSCDLF raw interrupt status. Writing 0 has no effect.
  [4] XOSCLFC — Writing 1 to this field clears the XOSCLF raw interrupt status. Writing 0 has no effect.
  [3] RCOSCDLFC — Writing 1 to this field clears the RCOSCDLF raw interrupt status. Writing 0 has no effect.
  [2] RCOSCLFC — Writing 1 to this field clears the RCOSCLF raw interrupt status. Writing 0 has no effect.
  [1] XOSCHFC — Writing 1 to this field clears the XOSCHF raw interrupt status. Writing 0 has no effect.
  [0] RCOSCHFC — Writing 1 to this field clears the RCOSCHF raw interrupt status. Writing 0 has no effect.
0x2B0 NVMNSCADDR — NVM Non-Secure Callable boundary Address
  [31] PARITY ro — Register parity bit.
  [19:10] BOUNDARY rw — Non-Secure callable boundary address. Writing this field when BUSSECCFG.VALID is set may result in undefined behavior.
0x2B4 NVMNSADDR reset 0x80100000 — NVM Non-Secure boundary Address
  [31] PARITY ro — Register parity bit
  [20] BOUNDARY_MSB ro — Non-Secure boundary address MSB HW controlled.
  [19:13] BOUNDARY rw — Non-Secure boundary address. Writing this field when BUSSECCFG.VALID is set may result in undefined behavior.
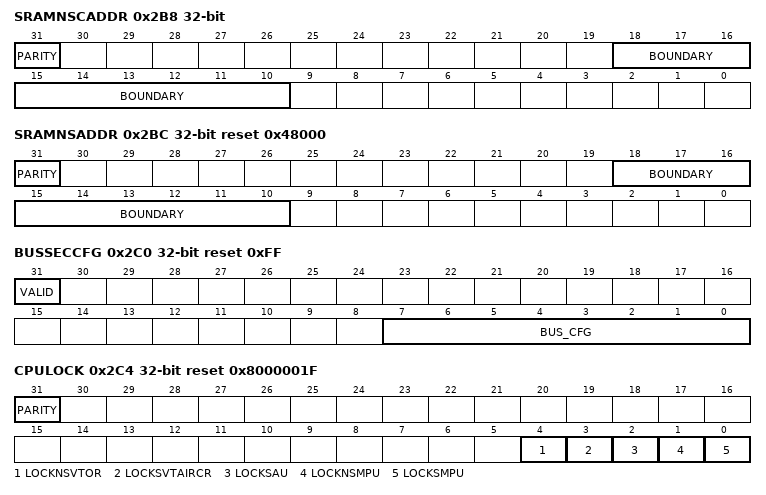
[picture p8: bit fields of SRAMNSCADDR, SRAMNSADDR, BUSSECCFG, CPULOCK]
0x2B8 SRAMNSCADDR — SRAM Non-Secure Callable boundary Address
  [31] PARITY ro — Register parity bit
  [18:10] BOUNDARY rw — Non-Secure callable boundary address. Writing this field when BUSSECCFG.VALID is set may result in undefined behavior.
0x2BC SRAMNSADDR reset 0x48000 — SRAM Non-Secure Callable boundary Address
  [31] PARITY ro — Register parity bit
  [18:10] BOUNDARY rw — Non-Secure boundary address. Writing this field when BUSSECCFG.VALID is set may result in undefined behavior.
0x2C0 BUSSECCFG reset 0xFF — BUS Security Configuration Register
  [31] VALID rw — Security configuration valid Registers that needs to be followed by VALID before settings being applied are: - NVMNSCADDR - NVMNSADDR - SRAMNSCADDR - SRAMNSADDR - BUSSECCFG - CPULOCK
  [7:0] BUS_CFG rw — Bus interconnect security and firewall configuration 0xFF : Trustzone enabled 0xF9 : Trustzone disabled Others: Reserved. Software should not rely on the value of reserved and should not write reserved settings.
0x2C4 CPULOCK reset 0x8000001F
  [31] PARITY ro — Register parity bit
  [4] LOCKNSVTOR rw — When set will lock non-secure vector table base address Writing this field when BUSSECCFG.VALID is set may result in undefined behavior.
  [3] LOCKSVTAIRCR rw — When set will lock - Secure vector table base address - Secure interrupt priority - Busfault - Hardfault NMI security target Writing this field when BUSSECCFG.VALID is set may result in undefined behavior.
  [2] LOCKSAU rw — When set will lock SAU regions Writing this field when BUSSECCFG.VALID is set may result in undefined behavior.
  [1] LOCKNSMPU rw — When set will lock non-secure MPU Writing this field when BUSSECCFG.VALID is set may result in undefined behavior.
  [0] LOCKSMPU rw — When set will lock secure MPU Writing this field when BUSSECCFG.VALID is set may result in undefined behavior.
